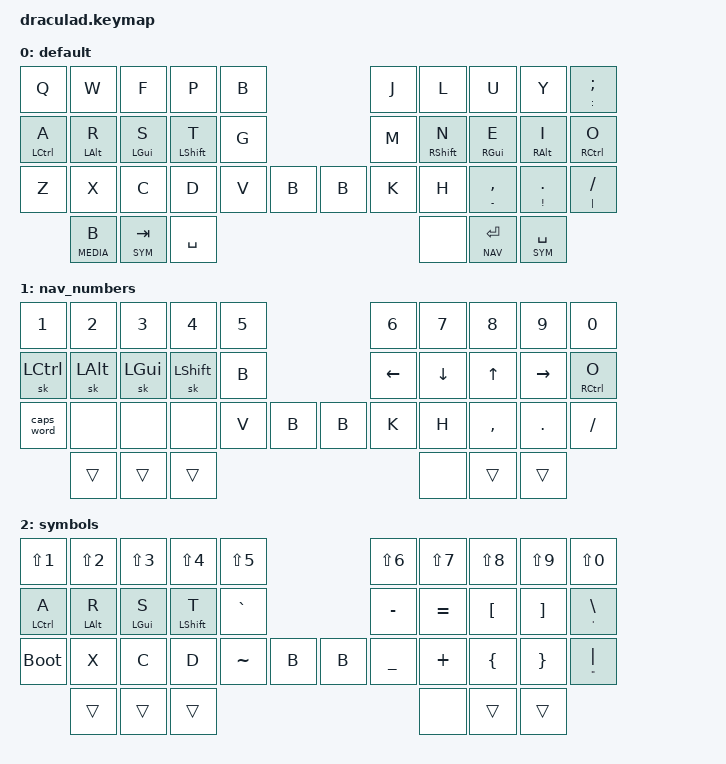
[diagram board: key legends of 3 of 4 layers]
/*
 * Copyright (c) 2020 The ZMK Contributors
 *
 * SPDX-License-Identifier: MIT
 */

#include <behaviors.dtsi>
#include <dt-bindings/zmk/keys.h>
#include <dt-bindings/zmk/bt.h>

// Layers
#define DEFAULT 0
#define NAV 1
#define SYM 2
#define MEDIA 3

/{
        behaviors {
                td0: tap_dance_0 {
                    compatible = "zmk,behavior-tap-dance";
                    #binding-cells = <0>;
                    tapping-term-ms = <200>;
                    bindings = <&kp G>, <&kp B>, <&kp N3>;
                };
                hm: homerow_mods {
                        compatible = "zmk,behavior-hold-tap";
                        label = "HOMEROW_MODS";
                        #binding-cells = <2>;
                        tapping-term-ms = <250>;
                        quick-tap-ms = <0>;
                        flavor = "tap-preferred";
                        bindings = <&kp>, <&kp>;
                };
                hplt: hold_preferred-lt {
                        compatible = "zmk,behavior-hold-tap";
                        label = "HOLD_PREFERRED_LT";
                        #binding-cells = <2>;
                        tapping-term-ms = <195>;
                        quick-tap-ms = <0>;
                        flavor = "hold-preferred";
                        bindings = <&mo>, <&kp>;
                };
                hms: homerow_mod_shift {
                        compatible = "zmk,behavior-hold-tap";
                        label = "HOMEROW_MOD_SHIFT";
                        #binding-cells = <2>;
                        tapping-term-ms = <170>;
                        quick-tap-ms = <0>;
                        flavor = "balanced";
                        bindings = <&kp>, <&kp>;
                };
                rpi: require_prior_idle {
                    compatible = "zmk,behavior-hold-tap";
                    #binding-cells = <2>;
                    flavor = "tap-preferred";
                    tapping-term-ms = <250>;
                    quick-tap-ms = <250>;
                    require-prior-idle-ms = <125>;
                    bindings = <&kp>, <&kp>;
                };
        };
        /* KEY POSITIONS
        ╭────────────────────╮ ╭────────────────────╮
        │  0   1   2   3   4 │ │  5   6   7   8   9 │
        │ 10  11  12  13  14 │ │ 15  16  17  18  19 │
        │ 20  21  22  23  24 │ │ 25  26  27  28  29 │
        ╰───────╮         30 │ │ 31       ╭─────────╯
                │ 32  33  34 │ │ 35 36 37 │
                ╰────────────╯ ╰──────────╯
        */
        combos {
                compatible = "zmk,combos";
                combo_esc {
                        timeout-ms = <50>;
                        key-positions = <0 1>;
                        bindings = <&kp ESC>;
                };
                combo_capslock {
                        timeout-ms = <50>;
                        key-positions = <10 11>;
                        bindings = <&kp CAPSLOCK>;
                };
                combo_enter {
                        timeout-ms = <50>;
                        key-positions = <18 19>;
                        bindings = <&kp ENTER>;
                };
                combo_copy {
                        timeout-ms = <50>;
                        key-positions = <13 23>;
                        bindings = <&kp LG(C)>;
                };
                combo_paste {
                        timeout-ms = <50>;
                        key-positions = <16 26>;
                        bindings = <&kp LG(V)>;
                };
                combo_parens_left {
                        timeout-ms = <50>;
                        key-positions = <3 13>;
                        bindings = <&kp LEFT_PARENTHESIS>;
                };
                combo_parens_right {
                        timeout-ms = <50>;
                        key-positions = <6 16>;
                        bindings = <&kp RIGHT_PARENTHESIS>;
                };
                combo_backspace {
                        timeout-ms = <50>;
                        key-positions = <8 9>;
                        bindings = <&kp BACKSPACE>;
                };
                combo_letter_b {
                        timeout-ms = <50>;
                        key-positions = <3 14>;
                        bindings = <&kp B>;
                };
        };
        keymap { compatible = "zmk,keymap";
                default {
                        /*
                                Q       W       E       R       T       Y       U       I       O       P
                                A       S       D       F       G       H       J       K       L       ;
                                Z       X       C       V       B       N       M       ,       .       /
                                                TAB     TAB     BSPC    SPC     TAB     TAB
                        */
                        // COLEMAK default
                        bindings = <
                                &kp Q           &kp W       &kp F       &kp P           &kp B                       &kp J   &kp L      &kp U           &kp Y          &rpi COLON SEMI
                                &rpi LCTRL A    &rpi LALT R &rpi LGUI S &rpi LSHFT T    &kp G                       &kp M   &hms RSHFT N   &hm RGUI E &hm RALT I      &hm RCTRL O
                                &kp Z           &kp X       &kp C       &kp D           &kp V      &kp B     &kp B  &kp K   &kp H      &mt MINUS COMMA &mt EXCL DOT   &mt PIPE FSLH
                                            &lt MEDIA B         &lt SYM TAB         &kp SPC                                   &none   &lt NAV ENTER   &lt SYM SPC
                        >;
                        // QWERTY, if that's how you roll
                        // bindings = <
                        //         &kp Q           &kp W           &kp E           &kp R           &kp T   &kp Y   &kp U           &kp I           &kp O           &kp P
                        //         &hm LCTRL A     &hm LALT S      &hm LGUI D      &hms LSHFT F    &kp G   &kp H   &hms RSHFT J    &hm RGUI K      &hm RALT L      &hm RCTRL SEMI
                        //         &kp Z           &kp X           &kp C           &kp V           &kp B   &kp N   &kp M           &kp COMMA       &kp DOT         &kp FSLH
                        //                         &kp TAB         &kp TAB         &kp BSPC        &kp SPC &kp TAB &kp TAB
                        // >;
                        // sensor-bindings = <&inc_dec_kp C_VOL_UP C_VOL_DN &inc_dec_kp PG_UP PG_DN>;
                        sensor-bindings = <&inc_dec_kp C_VOL_UP C_VOL_DN &inc_dec_kp PG_UP PG_DN>;
                };
                nav_numbers {
                        // numbers default
                        bindings = <
                                &kp N1     &kp N2   &kp N3      &kp N4      &kp N5                      &kp N6          &kp N7          &kp N8       &kp N9             &kp N0
                                &sk LCTRL  &sk LALT &sk LGUI    &sk LSHFT   &kp B                       &kp LEFT_ARROW  &kp DOWN_ARROW  &kp UP_ARROW &kp RIGHT_ARROW    &hm RCTRL O
                                &caps_word &none    &none       &none       &kp V   &kp B       &kp B   &kp K           &kp H           &kp COMMA    &kp DOT            &kp FSLH
                                                                &trans     &trans &trans             &none &trans    &trans
                        >;
                        // sensor-bindings = <&inc_dec_kp C_VOL_UP C_VOL_DN>;
                        sensor-bindings = <&inc_dec_kp C_VOL_UP C_VOL_DN &inc_dec_kp PG_UP PG_DN>;
                };
                symbols {
                        // Need to write these layers
                        // numbers default
                        bindings = <
                                &kp LS(N1)  &kp LS(N2)   &kp LS(N3)  &kp LS(N4)     &kp LS(N5)                  &kp LS(N6)  &kp LS(N7) &kp LS(N8)  &kp LS(N9)   &kp LS(N0)
                                &hm LCTRL A &hm LALT R   &hm LGUI S  &hms LSHFT T   &kp GRAVE                   &kp MINUS   &kp EQUAL  &kp LBKT    &kp RBKT     &mt SQT BSLH
                                &bootloader &kp X        &kp C       &kp D          &kp TILDE      &kp B &kp B  &kp UNDER   &kp PLUS   &kp LBRC    &kp RBRC     &mt DQT PIPE
                                                                &trans     &trans &trans             &none &trans    &trans
                        >;
                        // sensor-bindings = <&inc_dec_kp C_VOL_UP C_VOL_DN>;
                        sensor-bindings = <&inc_dec_kp C_VOL_UP C_VOL_DN &inc_dec_kp PG_UP PG_DN>;
                };
                media {
                        // Need to write these layers
                        // numbers default
                        bindings = <
                                &trans &trans &trans &trans &trans                      &trans &trans       &trans    &trans &trans
                                &trans &trans &trans &trans &trans                      &trans &kp K_VOL_DN    &kp K_VOL_UP &trans &trans
                                &trans &trans &trans &trans &trans                      &trans &trans       &trans    &trans &trans
                                                                &trans     &trans &trans             &trans &trans    &trans
                        >;
                        // sensor-bindings = <&inc_dec_kp C_VOL_UP C_VOL_DN>;
                        sensor-bindings = <&inc_dec_kp C_VOL_UP C_VOL_DN &inc_dec_kp PG_UP PG_DN>;
                };
        };
};
